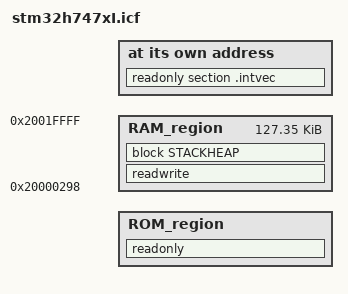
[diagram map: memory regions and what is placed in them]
//******************************************************************************
//* @attention
//*
//* Copyright (c) 2019 STMicroelectronics.
//* All rights reserved.
//*
//* This software component is licensed by ST under BSD 3-Clause license,
//* the "License"; You may not use this file except in compliance with the
//* License. You may obtain a copy of the License at:
//*                        opensource.org/licenses/BSD-3-Clause
//*
//******************************************************************************

// 2MB FLASH (0x200000)
if (!isdefinedsymbol(MBED_APP_START)) { define symbol MBED_APP_START = 0x08000000; }
if (!isdefinedsymbol(MBED_APP_SIZE)) { define symbol MBED_APP_SIZE = 0x200000; }
if (!isdefinedsymbol(MBED_BOOT_STACK_SIZE)) { define symbol MBED_BOOT_STACK_SIZE = 0x400; }

define symbol __intvec_start__     = MBED_APP_START;
define symbol __region_ROM_start__ = MBED_APP_START;
define symbol __region_ROM_end__   = MBED_APP_START + MBED_APP_SIZE - 1;

// 128KB DTCM RAM (0x20000)
// Vector table dynamic copy: 166 vectors = 664 bytes (0x298) reserved
define symbol __NVIC_start__                  = 0x20000000;
define symbol __NVIC_end__                    = 0x20000297;
define symbol __region_RAM_start__            = 0x20000298; // Aligned on 8 bytes
define symbol __region_RAM_end__              = 0x20000000 + 0x20000 - 1;

// Memory regions
define memory mem with size = 4G;
define region ROM_region = mem:[from __region_ROM_start__ to __region_ROM_end__];
define region RAM_region = mem:[from __region_RAM_start__ to __region_RAM_end__];

// Stack and Heap
define symbol __size_cstack__ = MBED_BOOT_STACK_SIZE;
define symbol __size_heap__   = 0x10000; // 64KB
define block CSTACK    with alignment = 8, size = __size_cstack__   { };
define block HEAP      with alignment = 8, size = __size_heap__     { };
define block STACKHEAP with fixed order { block HEAP, block CSTACK };

initialize by copy with packing = zeros { readwrite };
do not initialize  { section .noinit };

place at address mem:__intvec_start__ { readonly section .intvec };

place in ROM_region   { readonly };
place in RAM_region   { readwrite, block STACKHEAP };
